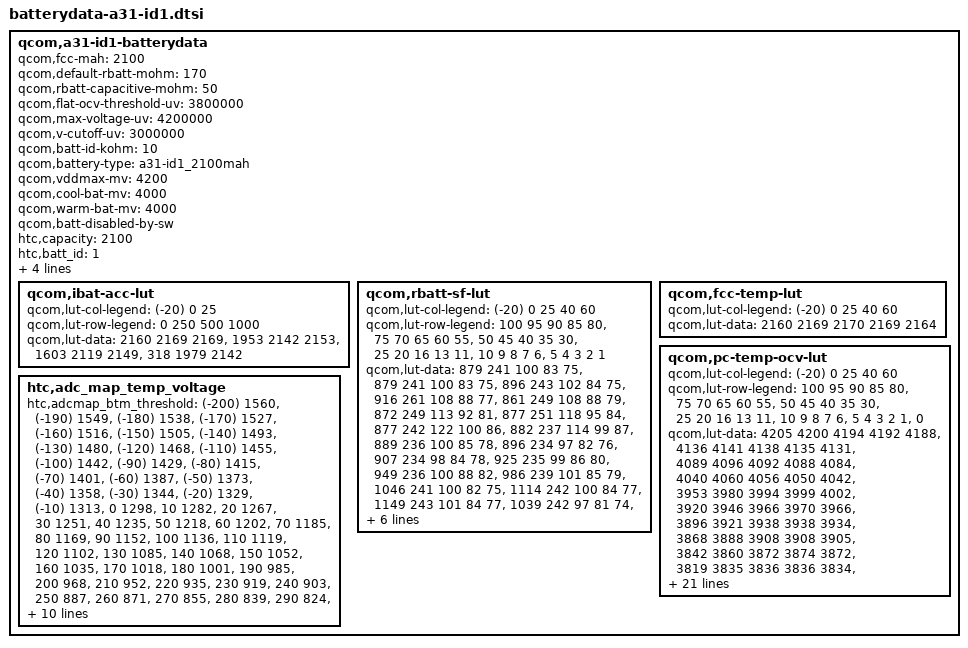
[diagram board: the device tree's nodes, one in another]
/* Copyright (c) 2013, The Linux Foundation. All rights reserved.
 *
 * This program is free software; you can redistribute it and/or modify
 * it under the terms of the GNU General Public License version 2 and
 * only version 2 as published by the Free Software Foundation.
 *
 * This program is distributed in the hope that it will be useful,
 * but WITHOUT ANY WARRANTY; without even the implied warranty of
 * MERCHANTABILITY or FITNESS FOR A PARTICULAR PURPOSE.  See the
 * GNU General Public License for more details.
 * Jiade battery
 */

 qcom,a31-id1-batterydata {
	qcom,fcc-mah = <2100>;
	qcom,default-rbatt-mohm = <170>;
	qcom,rbatt-capacitive-mohm = <50>;
	qcom,flat-ocv-threshold-uv = <3800000>;
	qcom,max-voltage-uv = <4200000>;
	qcom,v-cutoff-uv = <3000000>;
	qcom,batt-id-kohm = <10>;
	qcom,battery-type = "a31-id1_2100mah";
	qcom,vddmax-mv = <4200>;
	qcom,cool-bat-mv = <4000>;
	qcom,warm-bat-mv = <4000>;
	qcom,batt-disabled-by-sw;
	htc,capacity = <2100>;
	htc,batt_id = <1>;
	htc,id_raw_min = <1>;
	htc,id_raw_max = <1>;
	htc,type = <1>;
	htc,model_name = "B0PE6100";

	qcom,ibat-acc-lut {
		qcom,lut-col-legend = <(-20) 0 25>;
		qcom,lut-row-legend = <0 250 500 1000>;
		qcom,lut-data = <2160 2169 2169>,
				<1953 2142 2153>,
				<1603 2119 2149>,
				<318 1979 2142>;
	};

	qcom,rbatt-sf-lut {
		qcom,lut-col-legend = <(-20) 0 25 40 60>;
		qcom,lut-row-legend = <100 95 90 85 80>,
				<75 70 65 60 55>,
				<50 45 40 35 30>,
				<25 20 16 13 11>,
				<10 9 8 7 6>,
				<5 4 3 2 1>;
		qcom,lut-data = <879 241 100 83 75>,
				<879 241 100 83 75>,
				<896 243 102 84 75>,
				<916 261 108 88 77>,
				<861 249 108 88 79>,
				<872 249 113 92 81>,
				<877 251 118 95 84>,
				<877 242 122 100 86>,
				<882 237 114 99 87>,
				<889 236 100 85 78>,
				<896 234 97 82 76>,
				<907 234 98 84 78>,
				<925 235 99 86 80>,
				<949 236 100 88 82>,
				<986 239 101 85 79>,
				<1046 241 100 82 75>,
				<1114 242 100 84 77>,
				<1149 243 101 84 77>,
				<1039 242 97 81 74>,
				<987 242 96 81 75>,
				<1011 245 98 83 76>,
				<1046 249 100 85 79>,
				<1088 254 104 88 81>,
				<1145 258 107 91 82>,
				<1228 259 107 89 81>,
				<1367 259 104 87 79>,
				<1614 268 104 88 81>,
				<2126 284 108 90 84>,
				<4253 322 117 98 89>,
				<8506 645 151 119 113>;
	};

	qcom,fcc-temp-lut {
		qcom,lut-col-legend = <(-20) 0 25 40 60>;
		qcom,lut-data = <2160 2169 2170 2169 2164>;
	};

	qcom,pc-temp-ocv-lut {
		qcom,lut-col-legend = <(-20) 0 25 40 60>;
		qcom,lut-row-legend = <100 95 90 85 80>,
				<75 70 65 60 55>,
				<50 45 40 35 30>,
				<25 20 16 13 11>,
				<10 9 8 7 6>,
				<5 4 3 2 1>,
				<0>;
		qcom,lut-data = <4205 4200 4194 4192 4188>,
				<4136 4141 4138 4135 4131>,
				<4089 4096 4092 4088 4084>,
				<4040 4060 4056 4050 4042>,
				<3953 3980 3994 3999 4002>,
				<3920 3946 3966 3970 3966>,
				<3896 3921 3938 3938 3934>,
				<3868 3888 3908 3908 3905>,
				<3842 3860 3872 3874 3872>,
				<3819 3835 3836 3836 3834>,
				<3800 3814 3815 3814 3813>,
				<3785 3797 3799 3798 3796>,
				<3774 3784 3786 3786 3783>,
				<3764 3774 3776 3774 3772>,
				<3752 3766 3767 3762 3754>,
				<3737 3754 3754 3745 3732>,
				<3720 3738 3736 3727 3714>,
				<3700 3722 3715 3707 3694>,
				<3684 3711 3696 3687 3674>,
				<3670 3703 3690 3682 3670>,
				<3658 3700 3688 3680 3668>,
				<3646 3694 3686 3678 3668>,
				<3631 3689 3684 3677 3665>,
				<3612 3680 3680 3672 3660>,
				<3586 3660 3668 3658 3643>,
				<3552 3626 3636 3626 3609>,
				<3506 3578 3590 3580 3562>,
				<3438 3514 3528 3520 3502>,
				<3336 3424 3446 3438 3420>,
				<3196 3294 3323 3313 3294>,
				<3000 3000 3000 3000 3000>;
	};

	htc,adc_map_temp_voltage {
		htc,adcmap_btm_threshold = <(-200) 1560>,
								<(-190) 1549>,
								<(-180) 1538>,
								<(-170) 1527>,
								<(-160) 1516>,
								<(-150) 1505>,
								<(-140) 1493>,
								<(-130) 1480>,
								<(-120) 1468>,
								<(-110) 1455>,
								<(-100) 1442>,
								<(-90) 1429>,
								<(-80) 1415>,
								<(-70) 1401>,
								<(-60) 1387>,
								<(-50) 1373>,
								<(-40) 1358>,
								<(-30) 1344>,
								<(-20) 1329>,
								<(-10) 1313>,
								<0 1298>,
								<10 1282>,
								<20 1267>,
								<30 1251>,
								<40 1235>,
								<50 1218>,
								<60 1202>,
								<70 1185>,
								<80 1169>,
								<90 1152>,
								<100 1136>,
								<110 1119>,
								<120 1102>,
								<130 1085>,
								<140 1068>,
								<150 1052>,
								<160 1035>,
								<170 1018>,
								<180 1001>,
								<190 985>,
								<200 968>,
								<210 952>,
								<220 935>,
								<230 919>,
								<240 903>,
								<250 887>,
								<260 871>,
								<270 855>,
								<280 839>,
								<290 824>,
								<300 809>,
								<310 794>,
								<320 779>,
								<330 764>,
								<340 750>,
								<350 735>,
								<360 721>,
								<370 707>,
								<380 694>,
								<390 680>,
								<400 667>,
								<410 654>,
								<420 641>,
								<430 629>,
								<440 616>,
								<450 604>,
								<460 593>,
								<470 581>,
								<480 570>,
								<490 559>,
								<500 548>,
								<510 537>,
								<520 527>,
								<530 516>,
								<540 506>,
								<550 497>,
								<560 487>,
								<570 478>,
								<580 469>,
								<590 460>,
								<600 451>,
								<610 442>,
								<620 434>,
								<630 426>,
								<640 418>,
								<650 410>,
								<660 403>,
								<670 396>,
								<680 388>,
								<690 381>,
								<700 375>,
								<710 368>,
								<720 362>,
								<730 355>,
								<740 349>,
								<750 343>,
								<760 337>,
								<770 332>,
								<780 326>,
								<790 321>;
	};
};
